# link_layer_rx_model: IP-XACT component
VLNV IcronTechnologies:IcronTechnologies:link_layer_rx_model:1.0

## Parameters
addr_width = 9
bus_width = 32

## Bus interfaces (logical=physical port)
default_map: slave AGNISYS:AGNISYS:APB:1.0, memory map link_layer_rxmap
  pclk=pclk, presetn=presetn, psel=psel, penable=penable, pwrite=pwrite, pprot=pprot, pstrb=pstrb, pwdata=pwdata, paddr=paddr, pready=pready, prdata=prdata, pslverr=pslverr

## Ports
in pclk
in presetn
in psel
in penable
in pwrite
in pprot[2:0]
in pstrb[(bus_width div 8 )-1:0]
in pwdata[bus_width -1:0]
in paddr[addr_width -1:0]
out pready
out prdata[bus_width -1:0]
out pslverr
out link_layer_rx_regsversion_major_r[7:0]
out link_layer_rx_regsversion_minor_r[7:0]
out link_layer_rx_regsversion_patch_r[7:0]
out link_layer_rx_regsmac_client_interface_client_array_client_config_enb
out link_layer_rx_regsmac_client_interface_client_array_client_config_client_flow_ctrl_en_r
out link_layer_rx_regsmac_client_interface_client_array_client_config_client_en_r
out link_layer_rx_regsmac_client_interface_client_array_da_filter_word1_enb
out link_layer_rx_regsmac_client_interface_client_array_da_filter_word1_da_filter_w1_r[15:0]
out link_layer_rx_regsmac_client_interface_client_array_da_filter_word0_enb
out link_layer_rx_regsmac_client_interface_client_array_da_filter_word0_da_filter_w0_r[31:0]
out link_layer_rx_regsmac_client_interface_client_array_da_filter_mask_word1_enb
out link_layer_rx_regsmac_client_interface_client_array_da_filter_mask_word1_da_filter_mask_w1_r[15:0]
out link_layer_rx_regsmac_client_interface_client_array_da_filter_mask_word0_enb
out link_layer_rx_regsmac_client_interface_client_array_da_filter_mask_word0_da_filter_mask_w0_r[31:0]
out link_layer_rx_regsmac_client_interface_client_array_sa_filter_word1_enb
out link_layer_rx_regsmac_client_interface_client_array_sa_filter_word1_sa_filter_w1_r[15:0]
out link_layer_rx_regsmac_client_interface_client_array_sa_filter_word0_enb
out link_layer_rx_regsmac_client_interface_client_array_sa_filter_word0_sa_filter_w0_r[31:0]
out link_layer_rx_regsmac_client_interface_client_array_sa_filter_mask_word1_enb
out link_layer_rx_regsmac_client_interface_client_array_sa_filter_mask_word1_sa_filter_mask_w1_r[15:0]
out link_layer_rx_regsmac_client_interface_client_array_sa_filter_mask_word0_enb
out link_layer_rx_regsmac_client_interface_client_array_sa_filter_mask_word0_sa_filter_mask_w0_r[31:0]
out link_layer_rx_regsmac_client_interface_client_array_lt_filter_enb
out link_layer_rx_regsmac_client_interface_client_array_lt_filter_lt_filter_r[15:0]
out link_layer_rx_regsmac_client_interface_client_array_lt_filter_mask_enb
out link_layer_rx_regsmac_client_interface_client_array_lt_filter_mask_lt_filter_mask_r[15:0]
out link_layer_rx_regsmac_client_interface_client_array_stats0_rd2clr_config_rd_valid_out
out link_layer_rx_regsmac_client_interface_client_array_stats0_rd2clr_config_wr_valid_out
out link_layer_rx_regsmac_client_interface_client_array_stats0_out_eop_rd_valid_out
out link_layer_rx_regsmac_client_interface_client_array_stats0_out_sop_rd_valid_out
out link_layer_rx_regsmac_client_interface_client_array_stats0_filter_fifo_overflow_rd_valid_out
out link_layer_rx_regsmac_client_interface_client_array_stats0_drop_pkt_md_rd_valid_out
out link_layer_rx_regsmac_client_interface_client_array_stats0_drop_pkt_lt_rd_valid_out
out link_layer_rx_regsmac_client_interface_client_array_stats0_drop_pkt_sa_rd_valid_out
out link_layer_rx_regsmac_client_interface_client_array_stats0_drop_pkt_da_rd_valid_out
out link_layer_rx_regsmac_client_interface_client_array_stats0_one_cycle_pkt_rd_valid_out
out link_layer_rx_regsmac_client_interface_client_array_stats0_in_fsm_rollover_rd_valid_out
out link_layer_rx_regsmac_mac_config_enb
out link_layer_rx_regsmac_mac_config_inject_crc32_err_r
out link_layer_rx_regsmac_mac_config_disable_crc32_r
out link_layer_rx_regsmac_mac_config_dbg_seq_num_en_r
out link_layer_rx_regsmac_mac_config_en_r
out link_layer_rx_regsmac_da_word1_enb
out link_layer_rx_regsmac_da_word1_da_w1_r[15:0]
out link_layer_rx_regsmac_da_word0_enb
out link_layer_rx_regsmac_da_word0_da_w0_r[31:0]
out link_layer_rx_regsmac_pfifo_write_engine_config0_clear_enb
out link_layer_rx_regsmac_pfifo_write_engine_config0_clear_wclr_r
out link_layer_rx_regsmac_pfifo_write_engine_config0_mode_enb
out link_layer_rx_regsmac_pfifo_write_engine_config0_mode_drp_on_sop_r
out link_layer_rx_regsmac_pfifo_write_engine_config0_mode_drp_on_pkt_err_r
out link_layer_rx_regsmac_pfifo_write_engine_config0_mode_pkt_strm_r
out link_layer_rx_regsmac_pfifo_write_engine_config0_mode_flw_ctrl_en_r
out link_layer_rx_regsmac_pfifo_write_engine_config0_notify_limit_enb
out link_layer_rx_regsmac_pfifo_write_engine_config0_notify_limit_ntfy_lmt_r[31:0]
out link_layer_rx_regsmac_pfifo_write_engine_stats0_rd2clr_config_rd_valid_out
out link_layer_rx_regsmac_pfifo_write_engine_stats0_rd2clr_config_wr_valid_out
out link_layer_rx_regsmac_pfifo_write_engine_stats0_nfifo_dcount_rd_valid_out
out link_layer_rx_regsmac_pfifo_write_engine_stats0_pfifo_dcount_rd_valid_out
out link_layer_rx_regsmac_pfifo_write_engine_stats0_pkt_max_byte_cnt_err_rd_valid_out
out link_layer_rx_regsmac_pfifo_write_engine_stats0_fifo_full_err_rd_valid_out
out link_layer_rx_regsmac_pfifo_write_engine_stats0_pkt_err_rd_valid_out
out link_layer_rx_regsmac_pfifo_write_engine_stats0_pkt_sop_err_rd_valid_out
out link_layer_rx_regsmac_pfifo_write_engine_stats0_wflush_act_rd_valid_out
out link_layer_rx_regsmac_pfifo_write_engine_stats0_drp_pkt_rd_rd_valid_out
out link_layer_rx_regsmac_pfifo_write_engine_stats0_drp_pkt_wr_rd_valid_out
out link_layer_rx_regsmac_pfifo_write_engine_stats0_flow_ctrl_rd_valid_out
out link_layer_rx_regsmac_pfifo_read_engine_config0_clear_enb
out link_layer_rx_regsmac_pfifo_read_engine_config0_clear_rclr_r
out link_layer_rx_regsmac_pfifo_read_engine_stats0_rd2clr_config_rd_valid_out
out link_layer_rx_regsmac_pfifo_read_engine_stats0_rd2clr_config_wr_valid_out
out link_layer_rx_regsmac_pfifo_read_engine_stats0_rflush_act_rd_valid_out
out link_layer_rx_regsmac_pfifo_read_engine_stats0_drp_pkt_rd_valid_out
out link_layer_rx_regsmac_pfifo_read_engine_stats0_flow_ctrl_rd_valid_out
out link_layer_rx_regsmac_stats0_rd2clr_config_rd_valid_out
out link_layer_rx_regsmac_stats0_rd2clr_config_wr_valid_out
out link_layer_rx_regsmac_stats0_pause_frame_rd_valid_out
out link_layer_rx_regsmac_stats0_out_eop_rd_valid_out
out link_layer_rx_regsmac_stats0_out_sop_rd_valid_out
out link_layer_rx_regsmac_stats0_inbuf_eop_rd_valid_out
out link_layer_rx_regsmac_stats0_inbuf_sop_rd_valid_out
out link_layer_rx_regsmac_stats0_in_eop_rd_valid_out
out link_layer_rx_regsmac_stats0_in_sop_rd_valid_out
out link_layer_rx_regsmac_stats0_crc_err_rd_valid_out
out link_layer_rx_regsmac_stats0_out_fsm_rollover_rd_valid_out
out link_layer_rx_regsmac_stats0_in_fsm_rollover_rd_valid_out
out link_layer_rx_regsmac_stats0_dbg_seq_num_in_err_rd_valid_out
out link_layer_rx_regsmedia_rs_enable_enb
out link_layer_rx_regsmedia_rs_enable_rx_xgmii_en_r
out link_layer_rx_regsmedia_rs_enable_rx_gmii_en_r
out link_layer_rx_regsmedia_rs_pa_word1_enb
out link_layer_rx_regsmedia_rs_pa_word1_pa_word1_r[23:0]
out link_layer_rx_regsmedia_rs_pa_word0_enb
out link_layer_rx_regsmedia_rs_pa_word0_pa_word0_r[31:0]
out link_layer_rx_regsmedia_rs_sfd_enb
out link_layer_rx_regsmedia_rs_sfd_sfd_r[7:0]
out link_layer_rx_regsmedia_rs_idle_enb
out link_layer_rx_regsmedia_rs_idle_idle_r[7:0]
out link_layer_rx_regsmedia_rs_stats0_rd2clr_config_rd_valid_out
out link_layer_rx_regsmedia_rs_stats0_rd2clr_config_wr_valid_out
out link_layer_rx_regsmedia_rs_stats0_gmii_out_eop_rd_valid_out
out link_layer_rx_regsmedia_rs_stats0_gmii_out_sop_rd_valid_out
out link_layer_rx_regsmedia_rs_stats0_gmii_data_error_rd_valid_out
out link_layer_rx_regsmedia_rs_stats0_gmii_missing_sfd_rd_valid_out
out link_layer_rx_regsmedia_rs_stats1_rd2clr_config_rd_valid_out
out link_layer_rx_regsmedia_rs_stats1_rd2clr_config_wr_valid_out
out link_layer_rx_regsmedia_rs_stats1_xgmii_out_eop_rd_valid_out
out link_layer_rx_regsmedia_rs_stats1_xgmii_out_sop_rd_valid_out
out link_layer_rx_regsmedia_rs_stats1_xgmii_data_error_rd_valid_out
out link_layer_rx_regsmedia_rs_stats1_xgmii_missing_sfd_rd_valid_out
out link_layer_rx_regsmedia_rs_stats1_xgmii_wrong_lane_start_rd_valid_out
out link_layer_rx_regsmedia_rs_stats1_xgmii_link_ok_rd_valid_out
out link_layer_rx_regsmedia_rs_stats1_xgmii_local_fault_rd_valid_out
out link_layer_rx_regsmedia_rs_stats1_xgmii_remote_fault_rd_valid_out
out link_layer_rx_regsmedia_rs_stats1_xgmii_link_int_rd_valid_out
out link_layer_rx_regsmedia_rs_stats1_xgmii_runt_frm_detected_rd_valid_out
out link_layer_rx_regsptp_guard_config0_fix_ptp_violations_enb
out link_layer_rx_regsptp_guard_config0_fix_ptp_violations_activate_r
out link_layer_rx_regsptp_guard_config0_max_cycles_enb
out link_layer_rx_regsptp_guard_config0_max_cycles_max_cycle_mode_r[3:0]
out link_layer_rx_regsptp_guard_config0_max_cycles_max_cycles_r[15:0]
out link_layer_rx_regsptp_guard_stats0_rd2clr_config_rd_valid_out
out link_layer_rx_regsptp_guard_stats0_rd2clr_config_wr_valid_out
out link_layer_rx_regsptp_guard_stats0_missing_sop_err_rd_valid_out
out link_layer_rx_regsptp_guard_stats0_missing_eop_err_rd_valid_out
out link_layer_rx_regsptp_guard_stats0_max_cycle_err_rd_valid_out
out link_layer_rx_regsself_test_support_set_up_enb
out link_layer_rx_regsself_test_support_set_up_enable_r
out link_layer_rx_regsself_test_support_media_analyzer_stats0_rd2clr_config_rd_valid_out
out link_layer_rx_regsself_test_support_media_analyzer_stats0_rd2clr_config_wr_valid_out
out link_layer_rx_regsself_test_support_media_analyzer_stats0_lane_err_rd_valid_out
out link_layer_rx_regsself_test_support_media_analyzer_stats0_error_count_rd_valid_out
out link_layer_rx_regsself_test_support_media_analyzer_stats0_pkt_count_rd_valid_out
out link_layer_rx_regsself_test_support_de_framer_jumbo_lt_code_enb
out link_layer_rx_regsself_test_support_de_framer_jumbo_lt_code_jumbo_lt_code_r[15:0]

## Address spaces and blocks
link_layer_rxmap.link_layer_rx: base 0x000, range 0x200, width 32

## Registers
Registers are 32-bit, read-only, reset 0x0 unless marked. A register's access mark holds for its fields unless they carry their own. Offsets are from the block's base; lines under a group give offsets from that group; [hi:lo] are bit positions; {n}, {i} and the like mark numbered series; 'fields as' and 'values as' point back to an identical list; <NAME> marks a mode.

## link_layer_rxmap.link_layer_rx — Link Layer RX Registers
Base 0x00000000
0x00 version reset 0x60300 — 6.1.0: Added registers to disable/enable CRC32 check. 6.2.0: Changed the Interrupt Pending to avoid blocking the register update when enable is 0 6.3.0: Added pending_irq register
  [23:16] major — Major version
  [15:8] minor — Minor version
  [7:0] patch — Patch version
0x04 mac_client_interface group — Registers needed for the Clients
  0x00 version reset 0x10000
    fields as version
  0x04 client_array group — Registers needed for the Clients Array
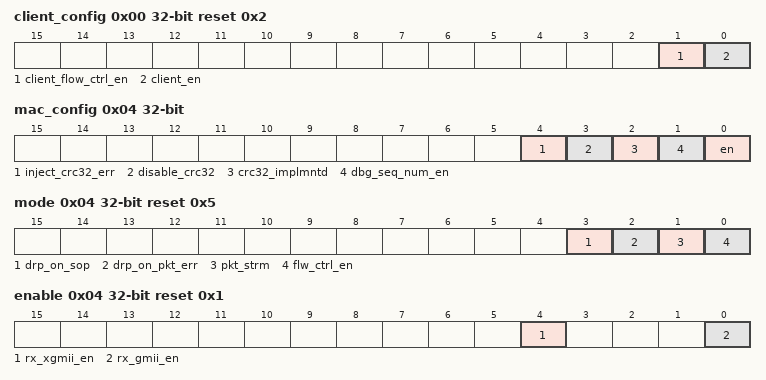
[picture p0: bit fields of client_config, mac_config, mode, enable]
    0x00 client_config rw reset 0x2
      [1] client_flow_ctrl_en — When set to 1, it enables the flow control feature of that client, whereby the client drdy is monitored in this block before presenting the next cycle of the PTP. When set to 0, it disables the flow control and the PTP traffic is presented without "listening" the drdy from the client.
      [0] client_en — When set to 1, it enables the flow of traffic to the client. When 0, the port is disabled and no traffic is presented to the client.
    0x04 da_filter_word1 rw reset 0xDADA — Destination Address Filter Word1
      [15:0] da_filter_w1 — This is the MAC Destination address allowed to pass (upper 2 bytes [47:32])
    0x08 da_filter_word0 rw reset 0xDADADADA — Destination Address Filter Word0
      [31:0] da_filter_w0 — This is the MAC Destination address allowed to pass (lower 4 bytes [31:0])
    0x0C da_filter_mask_word1 rw — Destination Address Filter Mask Word1
      [15:0] da_filter_mask_w1 — This is the Mask for the MAC Destination address allowed to pass (upper 2 bytes [47:32]). Only the location with a "1" in this mask shall be compared in the Destination Address
    0x10 da_filter_mask_word0 rw — Destination Address Filter Mask Word0
      [31:0] da_filter_mask_w0 — This is the Mask for the MAC Destination address allowed to pass (lower 4 bytes [31:0]). Only the location with a "1" in this mask shall be compared in the Destination Address
    0x14 sa_filter_word1 rw reset 0x5A5A — Source Address Filter Word1
      [15:0] sa_filter_w1 — This is the MAC Source address allowed to pass (upper 2 bytes [47:32])
    0x18 sa_filter_word0 rw reset 0x5A5A5A5A — Source Address Filter Word0
      [31:0] sa_filter_w0 — This is the MAC Source address allowed to pass (lower 4 bytes [31:0])
    0x1C sa_filter_mask_word1 rw — Source Address Filter Mask Word1
      [15:0] sa_filter_mask_w1 — This is the Mask for the MAC Source address allowed to pass (upper 2 bytes [47:32]). Only the location with a "1" in this mask shall be compared in the Source Address
    0x20 sa_filter_mask_word0 rw — Source Address Filter Mask Word0
      [31:0] sa_filter_mask_w0 — This is the Mask for the MAC Source address allowed to pass (lower 4 bytes [31:0]). Only the location with a "1" in this mask shall be compared in the Source Address
    0x24 lt_filter rw reset 0x1717 — Length/Type Filter
      [15:0] lt_filter — This is the MAC type allowed to pass
    0x28 lt_filter_mask rw — Length/Type Filter Mask
      [15:0] lt_filter_mask — This is the Mask for the MAC Type allowed to pass. Only the location with a "1" in this mask shall be compared in the Type field.
    0x2C stats0 group — All the Statistic Registers and their configuration.
      0x00 rd2clr_config rw — Configures if the stats register read by s/w clears the read register. A 1 in any bit configures the h/w to clear the corresponding stats register after a s/w read of that stats register.
        [8] in_fsm_rollover, [7] one_cycle_pkt, [6] drop_pkt_da, [5] drop_pkt_sa, [4] drop_pkt_lt, [3] drop_pkt_md, [2] filter_fifo_overflow, [1] out_sop, [0] out_eop
      0x04 out_eop — Count of the PTP EOP seen on the output port to client
      0x08 out_sop — Count of the PTP SOP seen on the output to client
      0x0C filter_fifo_overflow — Count of the times the filter FIFO was overflowed
        [7:0] filter_fifo_overflow
      0x10 drop_pkt_md — Count of PTP packets dropped due to the MAC Datagram filter
        [15:0] drop_pkt_md
      0x14 drop_pkt_lt — Count of PTP packets dropped due to the Length/Type filter
        [15:0] drop_pkt_lt
      0x18 drop_pkt_sa — Count of PTP packets dropped due to the Source Address filter
        [15:0] drop_pkt_sa
      0x1C drop_pkt_da — Count of PTP packets dropped due to the Destination Address filter
        [15:0] drop_pkt_da
      0x20 one_cycle_pkt — Count of PTP packets that are one-cycle
        [15:0] one_cycle_pkt
      0x24 in_fsm_rollover — Count of the number of times the input FSM rolled over. This indicates an error in the function of this block
        [7:0] in_fsm_rollover
0x5C mac group
  0x00 version reset 0x20100 — 2.1.0: Added registers to disable/enable CRC32 check.
    fields as version
  0x04 mac_config access per field
    [4] inject_crc32_err rw — Assert high to ask the logic to insert one crc32 check error when CRC32 logic is implemented. Write a 1 and HW clears it when completed the action
    [3] disable_crc32 rw — When set to 1, and if the CRC32 logic is implemented, disables checking of correct CRC32.
    [2] crc32_implmntd ro — This is the synthesis parameter value used for CRC32 logic implementation. When 1, it shows the CRC32 logic has been implemented in the logic. Note that, typically CRC32 MUST be implemented in MAC. However, due to some timing issues, we may decide to not have the logic when the system is used in a point-to-point configuration.
    [1] dbg_seq_num_en rw — When set to 1 it enables the debug logic to check for consecutive sequence number. Typically, this and the corresponding register in the TX path should be configured before any traffic sent between the TX and RX. Otherwise, there will not be synchrony between the sent and expected sequence numbers for at least one time
    [0] en rw — When set to 1 it enables the block. NOTE USED.
  0x08 da_word1 rw reset 0xDADA — Destination Address Word1
    [15:0] da_w1 — This is the MAC Destination address (upper 2 bytes [47:32])
  0x0C da_word0 rw reset 0xDADADADA — Destination Address Word0
    [31:0] da_w0 — This is the MAC Destination address (lower 4 bytes [31:0])
  0x10 pfifo group
    0x00 version reset 0x10100 — Version 1.1.0: Added Icron Attributes for stats script generation
      fields as version
    0x04 write_engine group
      0x00 config0 group
        0x00 clear rw — Synchronous clear for the write clock domain
          [0] wclr
        0x04 mode rw reset 0x5
          [3] drp_on_sop — When set, drops the current packet without writing it to the buffer. See Wiki
          [2] drp_on_pkt_err — When set, removes the packet from the buffer without presenting it to the output interface upon the ERR bit being set before the notification point. See Wiki
          [1] pkt_strm — Selects packet based or streaming based behavior. See Wiki
          [0] flw_ctrl_en — Enables the flow control. See Wiki
        0x08 notify_limit rw
          [31:0] ntfy_lmt — Sets the number of words required to be written into the packet FIFO before a notification will be generated. See wiki
      0x0C stats0 group — All the Statistic Registers and their configuration for the Write Engine
        0x00 rd2clr_config rw — Configures if the stats register read by s/w clears the read register. A 1 in any bit configures the h/w to clear the corresponding stats register after a s/w read of that stats register.
          [9] flow_ctrl, [8] drp_pkt_wr, [7] drp_pkt_rd, [6] wflush_act, [5] pkt_sop_err, [4] pkt_err, [3] fifo_full_err, [2] pkt_max_byte_cnt_err, [1] pfifo_dcount, [0] nfifo_dcount
        0x04 nfifo_dcount — Current level for the notification FIFO in the PFIFO
          [15:0] nfifo_dcount — _icron_water_marker_ _icron_no_counter_
        0x08 pfifo_dcount — Current level for the packet FIFO in the PFIFO
          [15:0] pfifo_dcount — _icron_water_marker_ _icron_no_counter_
        0x0C pkt_max_byte_cnt_err — The count for capped packets in PFIFO write engine, as the result of reaching maximum size in the PFIFO
          [7:0] pkt_max_byte_cnt_err
        0x10 fifo_full_err — The count for either of PFIFO or NFIFO being full
          [7:0] fifo_full_err
        0x14 pkt_err — The count of packets tagged to be dropped later in the PFIFO read engine
          [7:0] pkt_err
        0x18 pkt_sop_err — The count of packets flushed in the PFIFO during the SOP phase
          [7:0] pkt_sop_err
        0x1C wflush_act — The count of capped packets in the PFIFO. Note that back-to-back packets are counted as one if they are both capped.
          [7:0] wflush_act — _icron_event_detect_rising_edge_
        0x20 drp_pkt_rd — The count of drop packets flagged to be dropped by the read engine
          [7:0] drp_pkt_rd
        0x24 drp_pkt_wr — The count of drop packets by the write engine
          [7:0] drp_pkt_wr
        0x28 flow_ctrl — The count of the clock cycles the DRDY is asserted low resulting in flow control
          [15:0] flow_ctrl
    0x3C read_engine group
      0x00 config0 group
        0x00 clear rw — Synchronous clear for the read clock domain
          [0] rclr
      0x04 stats0 group — All the Statistic Registers and their configuration for the Read Engine
        0x00 rd2clr_config rw — Configures if the stats register read by s/w clears the read register. A 1 in any bit configures the h/w to clear the corresponding stats register after a s/w read of that stats register.
          [2] flow_ctrl, [1] drp_pkt, [0] rflush_act
        0x04 rflush_act — The counts of number of packets flushed from the PFIFO.
          [7:0] rflush_act — _icron_event_detect_rising_edge_
        0x08 drp_pkt — The counts of drop packet in the PFIFO read engine
          [7:0] drp_pkt
        0x0C flow_ctrl — The count of the clock cycles the DRDY is asserted low resulting in flow control
          [15:0] flow_ctrl
  0x60 stats0 group — All the Statistic Registers and their configuration.
    0x00 rd2clr_config rw — Configures if the stats register read by s/w clears the read register. A 1 in any bit configures the h/w to clear the corresponding stats register after a s/w read of that stats register.
      [10] dbg_seq_num_in_err, [9] in_fsm_rollover, [8] out_fsm_rollover, [7] crc_err, [6] in_sop, [5] in_eop, [4] inbuff_sop, [3] inbuf_eop, [2] out_sop, [1] out_eop, [0] pause_frame
    0x04 pause_frame — Count of pause frames received
    0x08 out_eop — Count of the PTP EOP seen on the output port to Client Interface
    0x0C out_sop — Count of the PTP SOP seen on the output port to Client Interface
    0x10 inbuf_eop — Count of the EOP of the PTP packets saved into the input buffer
    0x14 inbuf_sop — Count of the SOP of the PTP packets saved into the input buffer
    0x18 in_eop — Count of the EOP of the PTP packets seen from the RS layer
    0x1C in_sop — Count of the EOP of the PTP packets seen from the RS layer
    0x20 crc_err — Count of packets with CRC error
    0x24 out_fsm_rollover — Count of the number of times the output FSM rolled over. This indicates an error in the function of this block
      [7:0] out_fsm_rollover
    0x28 in_fsm_rollover — Count of the number of times the input FSM rolled over. This indicates an error in the function of this block
      [7:0] in_fsm_rollover
    0x2C dbg_seq_num_in_err — Count of the number of times the Frame sequence number was in-error during debug mode. See also the dbg_seq_num_en
      [15:0] dbg_seq_num_in_err
0xEC media_rs group — Registers needed for the Media RS in the RX Path
  0x00 version reset 0x20000
    fields as version
  0x04 enable rw reset 0x1
    [4] rx_xgmii_en — When set to 1, and rx_gmii_en is 0, it enables the XGMII path
    [0] rx_gmii_en — When set to 1, and rx_xgmii_en is 0, it enables the GMII path
  0x08 pa_word1 rw reset 0x555555
    [23:0] pa_word1 — Preamble values (upper 3 bytes)
  0x0C pa_word0 rw reset 0x55555555
    [31:0] pa_word0 — Preamble values (lower 4 bytes)
  0x10 sfd rw reset 0xD5
    [7:0] sfd — The Start of Frame Delimiter (SFD)
  0x14 idle rw reset 0x1E
    [7:0] idle — Idle character
  0x18 stats0 group — All the Statistic Registers and their configuration for the GMII
    0x00 rd2clr_config rw — Configures if the stats register read by s/w clears the read register. A 1 in any bit configures the h/w to clear the corresponding stats register after a s/w read of that stats register.
      [3] gmii_missing_sfd, [2] gmii_data_error, [1] gmii_out_sop, [0] gmii_out_eop
    0x04 gmii_out_eop — Count of the PTP EOP seen on the output port to MAC as the result of traffic on the GMII input port
    0x08 gmii_out_sop — Count of the PTP SOP seen on the output port to MAC as the result of traffic on the GMII input port
    0x0C gmii_data_error — Count of the GMII data error per IEEE802.3 Section 35.2.2.9
      [15:0] gmii_data_error
    0x10 gmii_missing_sfd — Count of the GMII data not properly starting with an SFD resulting in dropping the frame per IEEE802.3 Section 35.2.2.7
      [15:0] gmii_missing_sfd
  0x2C stats1 group — All the Statistic Registers and their configuration for the XGMII
    0x00 rd2clr_config rw — Configures if the stats register read by s/w clears the read register. A 1 in any bit configures the h/w to clear the corresponding stats register after a s/w read of that stats register.
      [9] xgmii_runt_frm_detected, [8] xgmii_link_int, [7] xgmii_remote_fault, [6] xgmii_local_fault, [5] xgmii_link_ok, [4] xgmii_wrong_lane_start, [3] xgmii_missing_sfd, [2] xgmii_data_error, [1] xgmii_out_sop, [0] xgmii_out_eop
    0x04 xgmii_out_eop — Count of the PTP EOP seen on the output port to MAC as the result of traffic on the XGMII input port
    0x08 xgmii_out_sop — Count of the PTP SOP seen on the output port to MAC as the result of traffic on the XGMII input port
    0x0C xgmii_data_error — Count of the XGMII data error per IEEE802.3 Sections 46.3.2.3 & 46.3.3.1. The count is the number of "cycles" in which there is an error character and not the number of error bytes
      [15:0] xgmii_data_error
    0x10 xgmii_missing_sfd — Count of the XGMII data not having the SFD in lane 3 in the next cycle following the cycle where the "start character" appears in lane 0, resulting in dropping the frame per IEEE802.3 Sections 46.3.2.3 & 46.3.3.3
      [15:0] xgmii_missing_sfd
    0x14 xgmii_wrong_lane_start — Count of the XGMII frame not starting with the "start character" in Lane 0 per IEEE802.3 Sections 46.3.2.3 & 46.3.3.3
      [15:0] xgmii_wrong_lane_start
    0x18 xgmii_link_ok — Count of the XGMII entering in Link OK status per Section 46.3.4 for Link Fault Signaling
      [15:0] xgmii_link_ok
    0x1C xgmii_local_fault — Count of the XGMII entering in Link Local Fault status per Section 46.3.4 for Link Fault Signaling
      [15:0] xgmii_local_fault
    0x20 xgmii_remote_fault — Count of the XGMII entering in Link Remote Fault status per Section 46.3.4 for Link Fault Signaling
      [15:0] xgmii_remote_fault
    0x24 xgmii_link_int — Count of the XGMII entering in Link Interrupt status per Section 46.3.4 for Link Fault Signaling
      [15:0] xgmii_link_int
    0x28 xgmii_runt_frm_detected — Count of the XGMII runt frames detected. Runt frames are then extended to minimum size Ethernet frames and marked as bad
      [15:0] xgmii_runt_frm_detected
0x144 ptp_guard group
  0x00 version reset 0x30300 — 3.1.0: Fixed bug in Max Cycle Error where in certain mode the cycles were included in the count 3.2.0: Changed the Interrupt Pending to avoid blocking the register update when enable is 0 3.3.0: Added pending_irq register
    fields as version
  0x04 config0 group
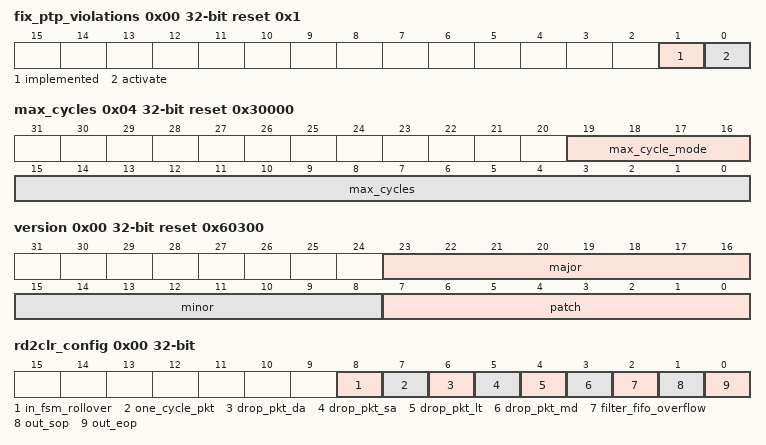
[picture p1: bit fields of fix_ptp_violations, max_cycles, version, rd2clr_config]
    0x00 fix_ptp_violations access per field reset 0x1
      [1] implemented ro — This is the synthesis parameter value used. When 1, it shows the PTP Guard fix logic has been implemented
      [0] activate rw — When 1, and if the fix logic is implemented, it instructs the PTP Guard to fix the PTP violations it detects (and reports). Note that there is a synthesis parameter to generate the "fix" logic or not When 0, no attempt is done to fix (even if the logic exists) and the PTP Guard will only work as a monitor and reports the violations detected. For full details of the operation, what violations are detected and fixed, and how the fix is done, see the wiki.
    0x04 max_cycles rw reset 0x30000
      [19:16] max_cycle_mode — This configures the mode of counting towards max_cycles: 0x0: All PTP cycles are included in the count 0x1: PTP cycles with backpressure (drdy=1'b0) are excluded from the count 0x2: PTP cycles with wait (srdy=1'b0) are excluded from the count 0x3: PTP cycles with either backpressure or wait are excluded from the count. Hence, only "absorbed" PTP cycles are included in the count Other mode values are reserved
      [15:0] max_cycles — Sets the maximum number of clock cycles the PTP packet can last between its sop and eop taking into account the max_cycle_mode When set to 0, it instructs the logic not to fix this violation (when the fix logic is available). However, the monitor will still issue a violation when the cycle count reaches its maximum and rollover.
  0x0C stats0 group — All the Statistic Registers and their configuration
    0x00 rd2clr_config rw — Configures if the stats register read by s/w clears the read register. A 1 in any bit configures the h/w to clear the corresponding stats register after a s/w read of that stats register.
      [2] max_cycle_err, [1] missing_eop_err, [0] missing_sop_err
    0x04 missing_sop_err — Counts the number of PTP violations due to missing sop where the srdy was asserted without a prior sop assertion
      [15:0] missing_sop_err
    0x08 missing_eop_err — Counts the number of PTP violations due to missing eop where the PTP had been started but a new sop is seen without ending the previously started PTP
      [15:0] missing_eop_err
    0x0C max_cycle_err — Counts the number of PTP violations due to reaching the maximum allowed cycles after starting a new PTP
      [15:0] max_cycle_err
  0x1C irq0 group — Define the IRQ group
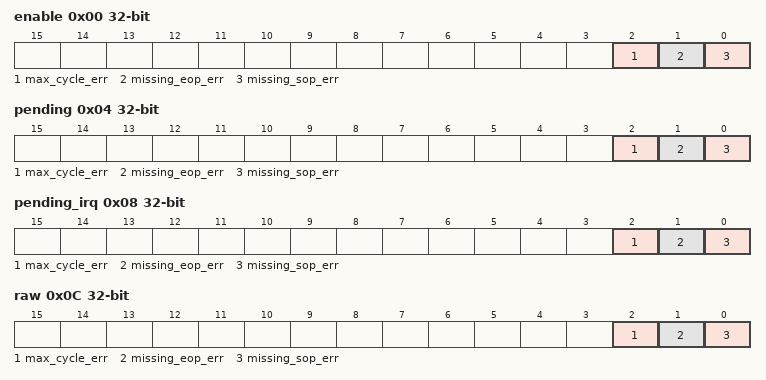
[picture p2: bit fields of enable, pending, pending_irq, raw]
    0x00 enable rw — The enable for the actual interrupt signals. Writing a 1 enables the interrupt.
      [2] max_cycle_err — Fires on PTP violations due to reaching the maximum allowed cycles after starting a new PTP
      [1] missing_eop_err — Fires on PTP violations due to missing eop where the PTP had been started but a new sop is seen without ending the previously started PTP
      [0] missing_sop_err — Fires on PTP violations due to missing sop where the srdy was asserted without a prior sop assertion
    0x04 pending rw — The actual interrupt(s) that has triggered. Write a 1 to clear.
      [2] max_cycle_err write-1-clears, [1] missing_eop_err write-1-clears, [0] missing_sop_err write-1-clears
    0x08 pending_irq — Registered version of pending & enable.
      [2] max_cycle_err, [1] missing_eop_err, [0] missing_sop_err
    0x0C raw — The status registered values for the interrupt signals, if applicable.
      [2] max_cycle_err — Not used
      [1] missing_eop_err — Not used
      [0] missing_sop_err — Not used
0x170 self_test_support group
  0x00 set_up rw reset 0x1
    [0] enable — Enables the self-test logic when it is 0x1, provided the proper parameter (p_impl_self_test) is set to "YES". All other traffic to the downstream blocks are inhibited.
  0x04 media_analyzer group — Registers needed for the Media Analyzer needed for self-test
    0x00 version reset 0x10000
      fields as version
    0x04 stats0 group — All the Statistic Registers and their configuration.
      0x00 rd2clr_config rw — Configures if the stats register read by s/w clears the read register. A 1 in any bit configures the h/w to clear the corresponding stats register after a s/w read of that stats register.
        [2] pkt_count, [1] error_count, [0] lane_err
      0x04 lane_err — Sticky bit (for each lane) showing an error in the received data of the corresponding lane
        [7:0] lane_err — Flags an error has occurred in a lane. This is a sticky flag. The lane_err[0] refers to Lane 0 (PTP bus [63 -:8]) and lane_err[7] to Lane 7 (PTP bus [08 -:8])
      0x08 error_count — Count of the number of errors in each clock cycle.
        [31:0] error_count — Count of the number of errors in each clock cycle. **Note** that there could be more than one byte in-error in each clock cycle and this count treats that as one error
      0x0C pkt_count — Count of the number of PTP Packets analyzed.
        [31:0] count — Count of the number of PTP packets processed at the analyzer. The count is generated when the eop is seen but it does not check if the sop was present
  0x18 de_framer group
    0x00 jumbo_lt_code rw reset 0x1717 — Type code used for Jumbo Frames
      [15:0] jumbo_lt_code
0x18C irq0 group — Define the IRQ group
  0x00 enable rw — The enable for the actual interrupt signals. Writing a 1 enables the interrupt.
    [3] link_int — Fires when the Link Layer is in Link Interrupt state
    [2] remote_fault — Fires when the Link Layer is in Remote Fault state
    [1] local_fault — Fires when the Link Layer is in Local Fault state
    [0] link_ok — Fires when the Link Layer is in Link OK state
  0x04 pending rw — The actual interrupt(s) that has triggered. Write a 1 to clear.
    [3] link_int write-1-clears — Fires when the Link Layer is in Link Interrupt state
    [2] remote_fault write-1-clears — Fires when the Link Layer is in Remote Fault state
    [1] local_fault write-1-clears — Fires when the Link Layer is in Local Fault state
    [0] link_ok write-1-clears — Fires when the Link Layer is in Link OK state
  0x08 pending_irq — Registered version of pending & enable
    fields as irq0.enable
  0x0C raw — The status registered values for the interrupt signals, if applicable.
    [3] link_int — Raw state when the Link Layer is in Link Interrupt state
    [2] remote_fault — Raw state when the Link Layer is in Remote Fault state
    [1] local_fault — Raw state when the Link Layer is in Local Fault state
    [0] link_ok — Raw state when the Link Layer is in Link OK state
